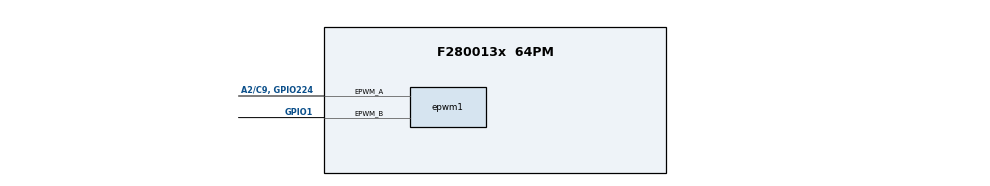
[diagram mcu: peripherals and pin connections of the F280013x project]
/**
 * @cliArgs --device "F280013x" --part "F280013x_64PM" --package "64PM" --context "system" --product "C2000WARE@5.05.00.00"
 * @versions {"tool":"1.24.0+4110"}
 */

/**
 * Import the modules used in this configuration.
 */
const epwm  = scripting.addModule("/driverlib/epwm.js", {}, false);
const epwm1 = epwm.addInstance();

/**
 * Write custom configuration values to the imported modules.
 */
epwm1.$name                                                     = "myEPWM0";
epwm1.epwmTimebase_counterMode                                  = "EPWM_COUNTER_MODE_UP_DOWN";
epwm1.epwmActionQualifier_EPWM_AQ_OUTPUT_A_onetimeSwForceAction = "EPWM_AQ_OUTPUT_HIGH";
epwm1.epwmActionQualifier_t1Source                              = "EPWM_AQ_TRIGGER_EVENT_TRIG_EPWM_SYNCIN";
epwm1.epwmActionQualifier_t2Source                              = "EPWM_AQ_TRIGGER_EVENT_TRIG_TZ_1";
epwm1.generateCodeTemplate                                      = true;
epwm1.epwm.epwm_aPin.$assign                                    = "A2/C9, GPIO224";
epwm1.epwm.epwm_bPin.$assign                                    = "GPIO1";

/**
 * Pinmux solution for unlocked pins/peripherals. This ensures that minor changes to the automatic solver in a future
 * version of the tool will not impact the pinmux you originally saw.  These lines can be completely deleted in order to
 * re-solve from scratch.
 */
epwm1.epwm.$suggestSolution = "EPWM1";
